AUTOSAR XML (schema 4.0)
standard types defined: float32, float64, sint16, sint32, sint8, uint16, uint32, uint8, void, boolean
package /ImplDataTypes
  4 x impl type, all with category=TYPE_REFERENCE, type-emitter=RTE:
    MultiStateBtnType: implementation-data-type=sint8
    SensorPositionType: implementation-data-type=sint32
    SensorWeightType: implementation-data-type=uint32
    StepMotorStepType: implementation-data-type=uint16
package /MappingSets
  data type mapping set MappingSet
package /PortInterfaces/ClientServer
  7 x client server interface:
    CsIf_HeightSensor
      operation Opr_HeightValue
        arg Height: type=SensorPositionType, direction=OUT
    CsIf_HeightStepMotor
      operation HeightMove
        arg step: type=StepMotorStepType, direction=INOUT
    CsIf_InclineSensor
      operation Opr_InclineValue
        arg Incline: type=MultiStateBtnType, direction=OUT
    CsIf_InclineStepMotor
      operation InclineMove
        arg step: type=StepMotorStepType, direction=INOUT
    CsIf_SlideSensor
      operation Opr_SlideValue
        arg Slide: type=SensorPositionType, direction=OUT
    CsIf_SlideStepMotor
      operation SlideMove
        arg step: type=StepMotorStepType, direction=INOUT
    CsIf_WeightSensor
      operation Opr_WeightValue
        arg Weight: type=SensorWeightType, direction=OUT
package /PortInterfaces/SenderReceiver
  sender receiver interface ppSeatCtrlBtns
    data HeightBtnState: type=MultiStateBtnType
    data InclineBtnState: type=MultiStateBtnType
    data SlideBtnState: type=MultiStateBtnType
  sender receiver interface rpSeatCtrlBtns
    data HeightBtnState: type=MultiStateBtnType
    data InclineBtnState: type=MultiStateBtnType
    data SlideBtnState: type=MultiStateBtnType
  sender receiver interface rpSeatCtrlData
    data Height: type=uint8
    data Incline: type=uint8
    data Slide: type=uint8
package /SoftwareComponents
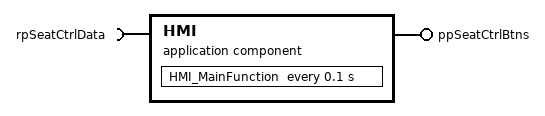
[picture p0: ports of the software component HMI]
  application sw component type HMI
    provide port ppSeatCtrlBtns: provided-interface=ppSeatCtrlBtns
    require port rpSeatCtrlData: required-interface=rpSeatCtrlData
    behavior Ibhv_HMI: data-type-mapping=MappingSet, handle-termination-and-restart=NO-SUPPORT
      timing event TE_HMI_MainFunction_100ms: start-on-event=HMI_MainFunction, period=0.1
      runnable HMI_MainFunction
        data-receive-point-by-arguments:
          access DRP_rpSeatCtrlData_Height: accessed-variable=rpSeatCtrlData.Height
          access DRP_rpSeatCtrlData_Incline: accessed-variable=rpSeatCtrlData.Incline
          access DRP_rpSeatCtrlData_Slide: accessed-variable=rpSeatCtrlData.Slide
        data-send-points:
          access DSP_ppSeatCtrlBtns_HeightBtnState: accessed-variable=ppSeatCtrlBtns.HeightBtnState
          access DSP_ppSeatCtrlBtns_InclineBtnState: accessed-variable=ppSeatCtrlBtns.InclineBtnState
          access DSP_ppSeatCtrlBtns_SlideBtnState: accessed-variable=ppSeatCtrlBtns.SlideBtnState
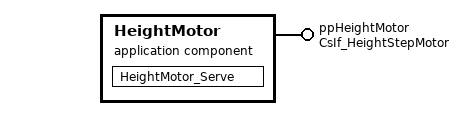
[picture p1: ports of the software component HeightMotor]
  application sw component type HeightMotor
    provide port ppHeightMotor: provided-interface=CsIf_HeightStepMotor
    behavior Ibhv_HeightMotor: data-type-mapping=MappingSet, handle-termination-and-restart=NO-SUPPORT
      operation invoked event OIE_ppHeightMotor_HeightMove: start-on-event=HeightMotor_Serve, operation=ppHeightMotor.HeightMove
      runnable HeightMotor_Serve
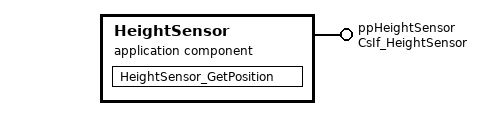
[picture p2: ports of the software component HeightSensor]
  application sw component type HeightSensor
    provide port ppHeightSensor: provided-interface=CsIf_HeightSensor
    behavior Ibhv_HeightSensor: data-type-mapping=MappingSet, handle-termination-and-restart=NO-SUPPORT
      operation invoked event OIE_ppHeightSensor_Opr_HeightValue: start-on-event=HeightSensor_GetPosition, operation=ppHeightSensor.Opr_HeightValue
      runnable HeightSensor_GetPosition
  9 x swc implementation, all with programming-language=C, sw-version=1.0.0, vendor-id=255:
    Impl_HMI: behavior=Ibhv_HMI
      code-descriptors:
        code Code: artifact-descriptors=autosar-engineering-object={short-label=SWC.c, category=SWSRC}
      resource consumption ResourceConsumption
    Impl_HeightMotor: behavior=Ibhv_HeightMotor
      code-descriptors:
        code Code: artifact-descriptors=autosar-engineering-object={short-label=SWC.c, category=SWSRC}
      resource consumption ResourceConsumption
    Impl_HeightSensor: behavior=Ibhv_HeightSensor
      code-descriptors:
        code Code: artifact-descriptors=autosar-engineering-object={short-label=SWC.c, category=SWSRC}
      resource consumption ResourceConsumption
    Impl_InclineMotor: behavior=Ibhv_InclineMotor
      code-descriptors:
        code Code: artifact-descriptors=autosar-engineering-object={short-label=SWC.c, category=SWSRC}
      resource consumption ResourceConsumption
    Impl_InclineSensor: behavior=Ibhv_InclineSensor
      code-descriptors:
        code Code: artifact-descriptors=autosar-engineering-object={short-label=SWC.c, category=SWSRC}
      resource consumption ResourceConsumption
    Impl_SeatManager: behavior=Ibhv_SeatManager
      code-descriptors:
        code Code: artifact-descriptors=autosar-engineering-object={short-label=SWC.c, category=SWSRC}
      resource consumption ResourceConsumption
    Impl_SlideMotor: behavior=Ibhv_SlideMotor
      code-descriptors:
        code Code: artifact-descriptors=autosar-engineering-object={short-label=SWC.c, category=SWSRC}
      resource consumption ResourceConsumption
    Impl_SlideSensor: behavior=Ibhv_SlideSensor
      code-descriptors:
        code Code: artifact-descriptors=autosar-engineering-object={short-label=SWC.c, category=SWSRC}
      resource consumption ResourceConsumption
    Impl_WeightSensor: behavior=Ibhv_WeightSensor
      code-descriptors:
        code Code: artifact-descriptors=autosar-engineering-object={short-label=SWC.c, category=SWSRC}
      resource consumption ResourceConsumption
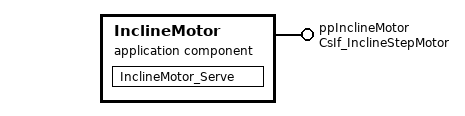
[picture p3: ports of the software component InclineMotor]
  application sw component type InclineMotor
    provide port ppInclineMotor: provided-interface=CsIf_InclineStepMotor
    behavior Ibhv_InclineMotor: data-type-mapping=MappingSet, handle-termination-and-restart=NO-SUPPORT
      operation invoked event OIE_ppInclineMotor_InclineMove: start-on-event=InclineMotor_Serve, operation=ppInclineMotor.InclineMove
      runnable InclineMotor_Serve
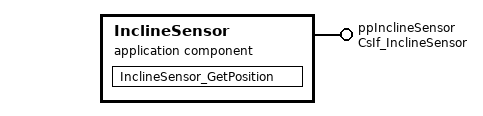
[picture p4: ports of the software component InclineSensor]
  application sw component type InclineSensor
    provide port ppInclineSensor: provided-interface=CsIf_InclineSensor
    behavior Ibhv_InclineSensor: data-type-mapping=MappingSet, handle-termination-and-restart=NO-SUPPORT
      operation invoked event OIE_ppInclineSensor_Opr_InclineValue: start-on-event=InclineSensor_GetPosition, operation=ppInclineSensor.Opr_InclineValue
      runnable InclineSensor_GetPosition
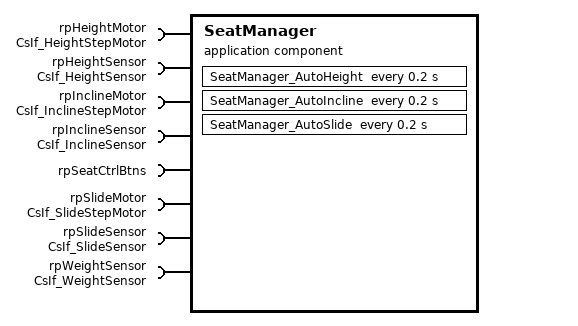
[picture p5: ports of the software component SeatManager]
  application sw component type SeatManager
    8 x require port:
      rpHeightMotor: required-interface=CsIf_HeightStepMotor
      rpHeightSensor: required-interface=CsIf_HeightSensor
      rpInclineMotor: required-interface=CsIf_InclineStepMotor
      rpInclineSensor: required-interface=CsIf_InclineSensor
      rpSeatCtrlBtns: required-interface=rpSeatCtrlBtns
      rpSlideMotor: required-interface=CsIf_SlideStepMotor
      rpSlideSensor: required-interface=CsIf_SlideSensor
      rpWeightSensor: required-interface=CsIf_WeightSensor
    behavior Ibhv_SeatManager: data-type-mapping=MappingSet, handle-termination-and-restart=NO-SUPPORT
      data received event DRE_rpSeatCtrlBtns_HeightBtnState: start-on-event=SeatManager_SetHeight, data=rpSeatCtrlBtns.HeightBtnState
      data received event DRE_rpSeatCtrlBtns_InclineBtnState: start-on-event=SeatManager_SetIncline, data=rpSeatCtrlBtns.InclineBtnState
      data received event DRE_rpSeatCtrlBtns_SlideBtnState: start-on-event=SeatManager_SetSlide, data=rpSeatCtrlBtns.SlideBtnState
      timing event TE_SeatManager_AutoHeight_200ms: start-on-event=SeatManager_AutoHeight, period=0.2
      timing event TE_SeatManager_AutoIncline_200ms: start-on-event=SeatManager_AutoIncline, period=0.2
      timing event TE_SeatManager_AutoSlide_200ms: start-on-event=SeatManager_AutoSlide, period=0.2
      6 x runnable:
        SeatManager_AutoHeight
          sync call SCP_rpHeightMotor_HeightMove: operation=rpHeightMotor.HeightMove, timeout=0.0
          sync call SCP_rpHeightSensor_Opr_HeightValue: operation=rpHeightSensor.Opr_HeightValue, timeout=0.0
          sync call SCP_rpWeightSensor_Opr_WeightValue: operation=rpWeightSensor.Opr_WeightValue, timeout=0.0
        SeatManager_AutoIncline
          sync call SCP_rpInclineMotor_InclineMove: operation=rpInclineMotor.InclineMove, timeout=0.0
          sync call SCP_rpInclineSensor_Opr_InclineValue: operation=rpInclineSensor.Opr_InclineValue, timeout=0.0
          sync call SCP_rpWeightSensor_Opr_WeightValue: operation=rpWeightSensor.Opr_WeightValue, timeout=0.0
        SeatManager_AutoSlide
          sync call SCP_rpSlideMotor_SlideMove: operation=rpSlideMotor.SlideMove, timeout=0.0
          sync call SCP_rpSlideSensor_Opr_SlideValue: operation=rpSlideSensor.Opr_SlideValue, timeout=0.0
          sync call SCP_rpWeightSensor_Opr_WeightValue: operation=rpWeightSensor.Opr_WeightValue, timeout=0.0
        SeatManager_SetHeight
          sync call SCP_rpHeightMotor_HeightMove: operation=rpHeightMotor.HeightMove, timeout=0.0
        SeatManager_SetIncline
          sync call SCP_rpInclineMotor_InclineMove: operation=rpInclineMotor.InclineMove, timeout=0.0
        SeatManager_SetSlide
          sync call SCP_rpSlideMotor_SlideMove: operation=rpSlideMotor.SlideMove, timeout=0.0
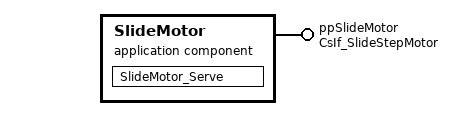
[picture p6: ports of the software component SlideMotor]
  application sw component type SlideMotor
    provide port ppSlideMotor: provided-interface=CsIf_SlideStepMotor
    behavior Ibhv_SlideMotor: data-type-mapping=MappingSet, handle-termination-and-restart=NO-SUPPORT
      operation invoked event OIE_ppSlideMotor_SlideMove: start-on-event=SlideMotor_Serve, operation=ppSlideMotor.SlideMove
      runnable SlideMotor_Serve
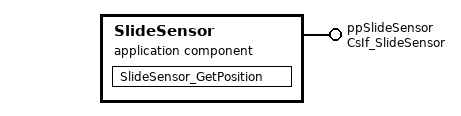
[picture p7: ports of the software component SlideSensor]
  application sw component type SlideSensor
    provide port ppSlideSensor: provided-interface=CsIf_SlideSensor
    behavior Ibhv_SlideSensor: data-type-mapping=MappingSet, handle-termination-and-restart=NO-SUPPORT
      operation invoked event OIE_ppSlideSensor_Opr_SlideValue: start-on-event=SlideSensor_GetPosition, operation=ppSlideSensor.Opr_SlideValue
      runnable SlideSensor_GetPosition
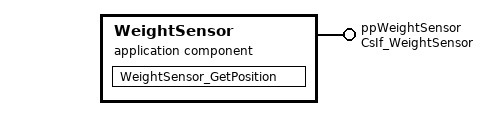
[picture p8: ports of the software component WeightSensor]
  application sw component type WeightSensor
    provide port ppWeightSensor: provided-interface=CsIf_WeightSensor
    behavior Ibhv_WeightSensor: data-type-mapping=MappingSet, handle-termination-and-restart=NO-SUPPORT
      operation invoked event OIE_ppWeightSensor_Opr_WeightValue: start-on-event=WeightSensor_GetPosition, operation=ppWeightSensor.Opr_WeightValue
      runnable WeightSensor_GetPosition
package /Compositions
  composition sw component type sender_resceiver_comComposition
